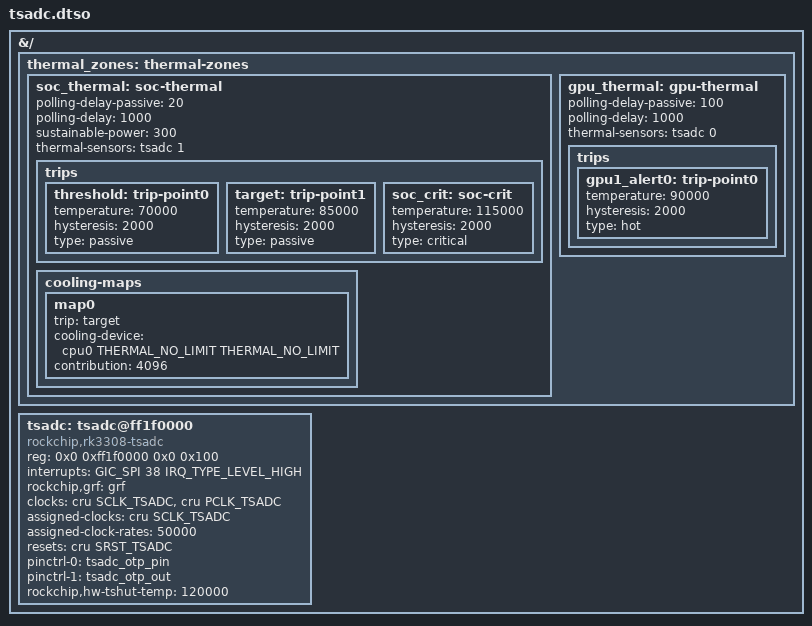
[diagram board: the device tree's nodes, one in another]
/dts-v1/;
/plugin/;

&{/} {
    #address-cells = <2>;
    #size-cells = <2>;
    thermal_zones: thermal-zones {
	soc_thermal: soc-thermal {
	    polling-delay-passive = <20>;
	    polling-delay = <1000>;
	    sustainable-power = <300>;

	    thermal-sensors = <&tsadc 1>;

	    trips {
		threshold: trip-point0 {
		    temperature = <70000>;
		    hysteresis = <2000>;
		    type = "passive";
		};
		target: trip-point1 {
		    temperature = <85000>;
		    hysteresis = <2000>;
		    type = "passive";
		};
		soc_crit: soc-crit {
		    temperature = <115000>;
		    hysteresis = <2000>;
		    type = "critical";
		};
	    };

	    cooling-maps {
		map0 {
		    trip = <&target>;
		    cooling-device = <&cpu0 THERMAL_NO_LIMIT THERMAL_NO_LIMIT>;
		    contribution = <4096>;
		};
	    };
	};

	gpu_thermal: gpu-thermal {
	    polling-delay-passive = <100>; /* milliseconds */
	    polling-delay = <1000>; /* milliseconds */

	    thermal-sensors = <&tsadc 0>;
            trips {
                gpu1_alert0: trip-point0 {
                    temperature = <90000>;
                    hysteresis = <2000>;
                    type = "hot";
                };
	    };
	};
    };

    tsadc: tsadc@ff1f0000 {
	compatible = "rockchip,rk3308-tsadc";
	reg = <0x0 0xff1f0000 0x0 0x100>;
	interrupts = <GIC_SPI 38 IRQ_TYPE_LEVEL_HIGH>;
	rockchip,grf = <&grf>;
	clocks = <&cru SCLK_TSADC>, <&cru PCLK_TSADC>;
	clock-names = "tsadc", "apb_pclk";
	assigned-clocks = <&cru SCLK_TSADC>;
	assigned-clock-rates = <50000>;
	resets = <&cru SRST_TSADC>;
	reset-names = "tsadc-apb";
	pinctrl-names = "gpio", "otpout";
	pinctrl-0 = <&tsadc_otp_pin>;
	pinctrl-1 = <&tsadc_otp_out>;
	#thermal-sensor-cells = <1>;
	rockchip,hw-tshut-temp = <120000>;
	status = "okay";
    };
};

